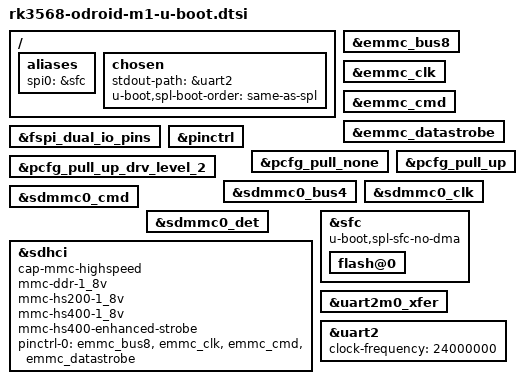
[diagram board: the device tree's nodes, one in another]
// SPDX-License-Identifier: GPL-2.0+
/*
 * (C) Copyright 2021 Rockchip Electronics Co., Ltd
 */

#include "rk356x-u-boot.dtsi"

/ {
	aliases {
		spi0 = &sfc;
	};

	chosen {
		stdout-path = &uart2;
		u-boot,spl-boot-order = "same-as-spl", &sdmmc0, &sdhci;
	};
};

&emmc_bus8 {
	bootph-all;
};

&emmc_clk {
	bootph-all;
};

&emmc_cmd {
	bootph-all;
};

&emmc_datastrobe {
	bootph-all;
};

&fspi_dual_io_pins {
	bootph-all;
};

&pinctrl {
	bootph-all;
};

&pcfg_pull_none {
	bootph-all;
};

&pcfg_pull_up_drv_level_2 {
	bootph-all;
};

&pcfg_pull_up {
	bootph-all;
};

&sdmmc0_bus4 {
	bootph-all;
};

&sdmmc0_clk {
	bootph-all;
};

&sdmmc0_cmd {
	bootph-all;
};

&sdmmc0_det {
	bootph-all;
};

&sdhci {
	cap-mmc-highspeed;
	mmc-ddr-1_8v;
	mmc-hs200-1_8v;
	mmc-hs400-1_8v;
	mmc-hs400-enhanced-strobe;
	pinctrl-0 = <&emmc_bus8 &emmc_clk &emmc_cmd &emmc_datastrobe>;
};

&sfc {
	bootph-pre-ram;
	u-boot,spl-sfc-no-dma;

	flash@0 {
		bootph-pre-ram;
	};
};

&uart2m0_xfer {
	bootph-all;
};

&uart2 {
	clock-frequency = <24000000>;
	bootph-all;
	status = "okay";
};
